# TM4C1294NCPDT register map
Vendor: Texas Instruments; File version: 2.2.0.295
CPU: CM4 r0p1, little endian, MPU, FPU, 3 interrupt priority bits
Registers are 32-bit, read-write, no defined reset value unless marked. A register's access mark holds for its fields unless they carry their own. Offsets are from the block's base; [hi:lo] are bit positions; {n}, {i} and the like mark numbered series; 'fields as' and 'values as' point back to an identical list.

## TIMER0 — Timer (TIMER0)
Base 0x40030000
Same registers: TIMER1 0x40031000, TIMER2 0x40032000, TIMER3 0x40033000, TIMER4 0x40034000, TIMER5 0x40035000, TIMER6 0x400E0000, TIMER7 0x400E1000
0x00 CFG
  [2] 16_BIT — For a 16/32-bit timer, this
  [2:0] VALUE — GPTM Configuration
  [0] 32_BIT_RTC — For a 16/32-bit timer, this
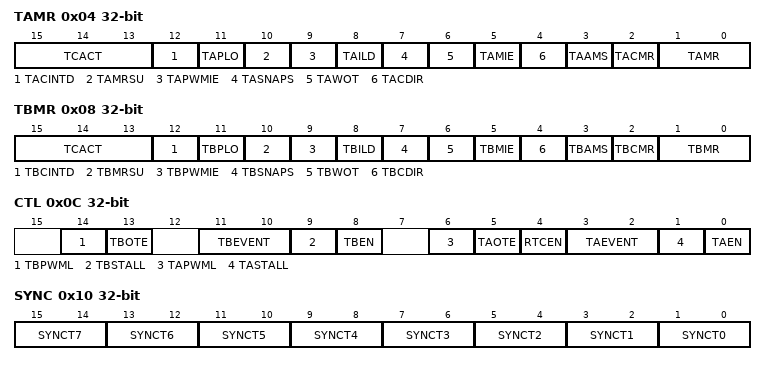
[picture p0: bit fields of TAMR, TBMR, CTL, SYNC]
0x04 TAMR
  [15:13] TCACT — Timer Compare Action Select
    0=NONE (Disable compare operations); 1=TOGGLE (Toggle State on Time-Out); 2=CLRTO (Clear CCP on Time-Out); 3=SETTO (Set CCP on Time-Out); 4=SETTOGTO (Set CCP immediately and toggle); 5=CLRTOGTO (Clear CCP immediately and toggle); 6=SETCLRTO (Set CCP immediately and clear on); 7=CLRSETTO (Clear CCP immediately and set on)
  [12] TACINTD — One-shot/Periodic Interrupt
  [11] TAPLO — GPTM Timer A PWM Legacy
  [10] TAMRSU — GPTM Timer A Match Register
  [9] TAPWMIE — GPTM Timer A PWM Interrupt
  [8] TAILD — GPTM Timer A Interval Load Write
  [7] TASNAPS — GPTM Timer A Snap-Shot Mode
  [6] TAWOT — GPTM Timer A Wait-on-Trigger
  [5] TAMIE — GPTM Timer A Match Interrupt
  [4] TACDIR — GPTM Timer A Count Direction
  [3] TAAMS — GPTM Timer A Alternate Mode
  [2] TACMR — GPTM Timer A Capture Mode
  [1:0] TAMR — GPTM Timer A Mode
    1=1_SHOT (One-Shot Timer mode); 2=PERIOD (Periodic Timer mode); 3=CAP (Capture mode)
0x08 TBMR
  [15:13] TCACT — Timer Compare Action Select
    values as TAMR.TCACT
  [12] TBCINTD — One-Shot/Periodic Interrupt
  [11] TBPLO — GPTM Timer B PWM Legacy
  [10] TBMRSU — GPTM Timer B Match Register
  [9] TBPWMIE — GPTM Timer B PWM Interrupt
  [8] TBILD — GPTM Timer B Interval Load Write
  [7] TBSNAPS — GPTM Timer B Snap-Shot Mode
  [6] TBWOT — GPTM Timer B Wait-on-Trigger
  [5] TBMIE — GPTM Timer B Match Interrupt
  [4] TBCDIR — GPTM Timer B Count Direction
  [3] TBAMS — GPTM Timer B Alternate Mode
  [2] TBCMR — GPTM Timer B Capture Mode
  [1:0] TBMR — GPTM Timer B Mode
    values as TAMR.TAMR
0x0C CTL
  [14] TBPWML — GPTM Timer B PWM Output Level
  [13] TBOTE — GPTM Timer B Output Trigger
  [11:10] TBEVENT — GPTM Timer B Event Mode
    0=POS (Positive edge); 1=NEG (Negative edge); 3=BOTH (Both edges)
  [9] TBSTALL — GPTM Timer B Stall Enable
  [8] TBEN — GPTM Timer B Enable
  [6] TAPWML — GPTM Timer A PWM Output Level
  [5] TAOTE — GPTM Timer A Output Trigger
  [4] RTCEN — GPTM RTC Stall Enable
  [3:2] TAEVENT — GPTM Timer A Event Mode
    values as TBEVENT
  [1] TASTALL — GPTM Timer A Stall Enable
  [0] TAEN — GPTM Timer A Enable
0x10 SYNC
  [15:14] SYNCT7 — Synchronize GPTM Timer 7
    0=NONE (GPT7 is not affected); 1=TA (A timeout event for Timer A of); 2=TB (A timeout event for Timer B of); 3=TATB (A timeout event for both Timer A)
  [2n+1:2n] SYNCT{n} (n=0..6) — Synchronize GPTM Timer {n}
    0=NONE (GPTM{n} is not affected); 1=TA (A timeout event for Timer A of); 2=TB (A timeout event for Timer B of); 3=TATB (A timeout event for both Timer A)
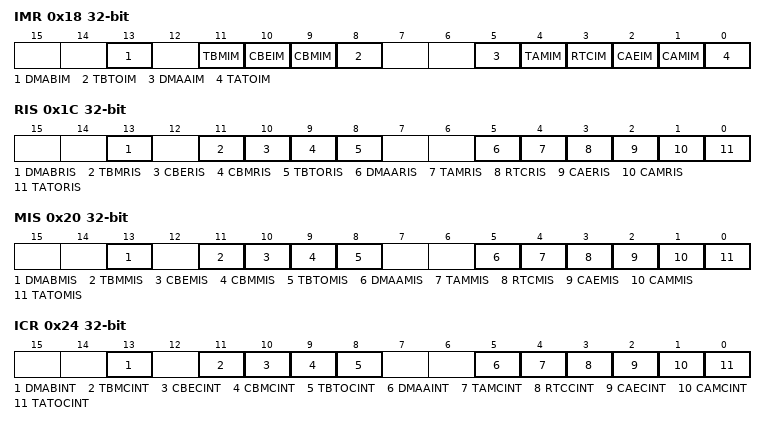
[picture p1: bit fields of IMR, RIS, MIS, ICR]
0x18 IMR
  [13] DMABIM — GPTM Timer B DMA Done Interrupt
  [11] TBMIM — GPTM Timer B Match Interrupt
  [10] CBEIM — GPTM Timer B Capture Mode Event
  [9] CBMIM — GPTM Timer B Capture Mode Match
  [8] TBTOIM — GPTM Timer B Time-Out Interrupt
  [5] DMAAIM — GPTM Timer A DMA Done Interrupt
  [4] TAMIM — GPTM Timer A Match Interrupt
  [3] RTCIM — GPTM RTC Interrupt Mask
  [2] CAEIM — GPTM Timer A Capture Mode Event
  [1] CAMIM — GPTM Timer A Capture Mode Match
  [0] TATOIM — GPTM Timer A Time-Out Interrupt
0x1C RIS
  [13] DMABRIS — GPTM Timer B DMA Done Raw
  [11] TBMRIS — GPTM Timer B Match Raw Interrupt
  [10] CBERIS — GPTM Timer B Capture Mode Event
  [9] CBMRIS — GPTM Timer B Capture Mode Match
  [8] TBTORIS — GPTM Timer B Time-Out Raw
  [5] DMAARIS — GPTM Timer A DMA Done Raw
  [4] TAMRIS — GPTM Timer A Match Raw Interrupt
  [3] RTCRIS — GPTM RTC Raw Interrupt
  [2] CAERIS — GPTM Timer A Capture Mode Event
  [1] CAMRIS — GPTM Timer A Capture Mode Match
  [0] TATORIS — GPTM Timer A Time-Out Raw
0x20 MIS
  [13] DMABMIS — GPTM Timer B DMA Done Masked
  [11] TBMMIS — GPTM Timer B Match Masked
  [10] CBEMIS — GPTM Timer B Capture Mode Event
  [9] CBMMIS — GPTM Timer B Capture Mode Match
  [8] TBTOMIS — GPTM Timer B Time-Out Masked
  [5] DMAAMIS — GPTM Timer A DMA Done Masked
  [4] TAMMIS — GPTM Timer A Match Masked
  [3] RTCMIS — GPTM RTC Masked Interrupt
  [2] CAEMIS — GPTM Timer A Capture Mode Event
  [1] CAMMIS — GPTM Timer A Capture Mode Match
  [0] TATOMIS — GPTM Timer A Time-Out Masked
0x24 ICR
  [13] DMABINT — GPTM Timer B DMA Done Interrupt
  [11] TBMCINT — GPTM Timer B Match Interrupt
  [10] CBECINT — GPTM Timer B Capture Mode Event
  [9] CBMCINT — GPTM Timer B Capture Mode Match
  [8] TBTOCINT — GPTM Timer B Time-Out Interrupt
  [5] DMAAINT — GPTM Timer A DMA Done Interrupt
  [4] TAMCINT — GPTM Timer A Match Interrupt
  [3] RTCCINT — GPTM RTC Interrupt Clear
  [2] CAECINT — GPTM Timer A Capture Mode Event
  [1] CAMCINT — GPTM Timer A Capture Mode Match
  [0] TATOCINT — GPTM Timer A Time-Out Raw
0x28 TAILR
  [31:0] VALUE — GPTM Timer A Interval Load
0x2C TBILR
  [31:0] VALUE — GPTM Timer B Interval Load
0x30 TAMATCHR
  [31:0] TAMR — GPTM Timer A Match Register
0x34 TBMATCHR
  [31:0] TBMR — GPTM Timer B Match Register
0x38 TAPR
  [7:0] TAPSR — GPTM Timer A Prescale
0x3C TBPR
  [7:0] TBPSR — GPTM Timer B Prescale
0x40 TAPMR
  [7:0] TAPSMR — GPTM TimerA Prescale Match
0x44 TBPMR
  [7:0] TBPSMR — GPTM TimerB Prescale Match
0x48 TAR
  [31:0] VALUE — GPTM Timer A Register
0x4C TBR
  [31:0] VALUE — GPTM Timer B Register
0x50 TAV
  [31:0] VALUE — GPTM Timer A Value
0x54 TBV
  [31:0] VALUE — GPTM Timer B Value
0x58 RTCPD
  [15:0] RTCPD — RTC Predivide Counter Value
0x5C TAPS
  [15:0] PSS — GPTM Timer A Prescaler Snapshot
0x60 TBPS
  [15:0] PSS — GPTM Timer A Prescaler Value
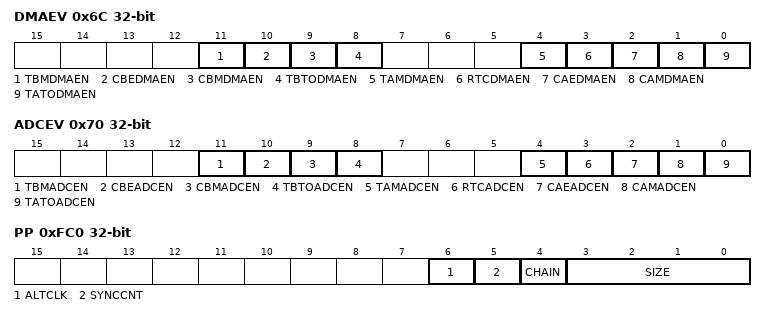
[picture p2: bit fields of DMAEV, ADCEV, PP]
0x6C DMAEV
  [11] TBMDMAEN — GPTM B Mode Match Event DMA
  [10] CBEDMAEN — GPTM B Capture Event DMA Trigger
  [9] CBMDMAEN — GPTM B Capture Match Event DMA
  [8] TBTODMAEN — GPTM B Time-Out Event DMA
  [4] TAMDMAEN — GPTM A Mode Match Event DMA
  [3] RTCDMAEN — GPTM A RTC Match Event DMA
  [2] CAEDMAEN — GPTM A Capture Event DMA Trigger
  [1] CAMDMAEN — GPTM A Capture Match Event DMA
  [0] TATODMAEN — GPTM A Time-Out Event DMA
0x70 ADCEV
  [11] TBMADCEN — GPTM B Mode Match Event ADC
  [10] CBEADCEN — GPTM B Capture Event ADC Trigger
  [9] CBMADCEN — GPTM B Capture Match Event ADC
  [8] TBTOADCEN — GPTM B Time-Out Event ADC
  [4] TAMADCEN — GPTM A Mode Match Event ADC
  [3] RTCADCEN — GPTM RTC Match Event ADC Trigger
  [2] CAEADCEN — GPTM A Capture Event ADC Trigger
  [1] CAMADCEN — GPTM A Capture Match Event ADC
  [0] TATOADCEN — GPTM A Time-Out Event ADC
0xFC0 PP
  [6] ALTCLK — Alternate Clock Source
  [5] SYNCCNT — Synchronize Start
  [4] CHAIN — Chain with Other Timers
  [3:0] SIZE — Count Size
    0=Timer A and Timer B counters are; 1=Timer A and Timer B counters are
0xFC8 CC
  [0] ALTCLK — Alternate Clock Source
